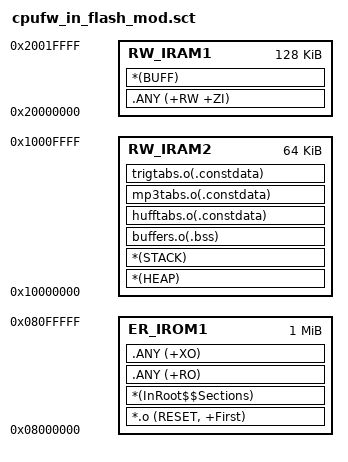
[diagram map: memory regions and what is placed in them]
; *************************************************************
; *** Scatter-Loading Description File generated by uVision ***
; *************************************************************

LR_IROM1 0x08000000 0x00100000  {    ; load region size_region
  ER_IROM1 0x08000000 0x00100000  {  ; load address = execution address
   *.o (RESET, +First)
   *(InRoot$$Sections)
   .ANY (+RO)
   .ANY (+XO)
  }
  RW_IRAM1 0x20000000 0x00020000  {  ; RW data
   ;app.o(+RO) 
  ; mp3dec.o(+RO)
   ;imdct.o(+RO)
   .ANY (+RW +ZI)
   ;mp3dec.o (+RO)
   *(BUFF)
   ;*(HEAP) 
  }
  RW_IRAM2 0x10000000 0x00010000  {
   *(HEAP)   
   *(STACK)   
  ; memp.o(.bss)
  ; mem.o(.bss)
  ; *(BUFF) 
  ; usbd_rndis_core.o(.bss)
   buffers.o(.bss)
   hufftabs.o(.constdata)
   mp3tabs.o(.constdata)
   trigtabs.o(.constdata)
  }
}

